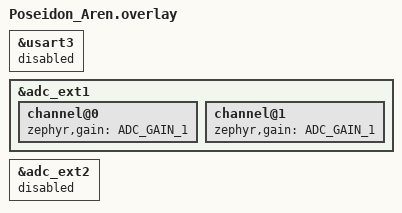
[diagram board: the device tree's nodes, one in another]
/*
 * Device-tree overlay for the "Poseidon_Aren" variant.
 *
 * Cell mix: 2x DiveO2 digital cells (CELL_COUNT=2).
 *
 *   Cell 1 = DiveO2  → USART1
 *   Cell 2 = DiveO2  → USART2
 *   (no Cell 3)      → USART3 unused
 *
 * No analog cells, but the first ADS1115 (adc_ext1 @0x48) is repurposed for
 * the HP tank pressure transducers (CONFIG_O2_TRANSDUCER_CHANNEL=0 /
 * CONFIG_DIL_TRANSDUCER_CHANNEL=1 in the matching .conf):
 *
 *   O2 transducer  → io-channels index 0 → adc_ext1 channel@0 (AIN0-AIN1)
 *   Dil transducer → io-channels index 1 → adc_ext1 channel@1 (AIN2-AIN3)
 *
 * The transducers swing 0.3–1.8 V, so the galvanic-cell PGA range of
 * ADC_GAIN_8 (±0.256 V) from the board DTS would clip: override both
 * channels to ADC_GAIN_1 (±2.048 V full scale).
 *
 * With only two digital cells USART3 is idle, and adc_ext2 (cell 3 + aux)
 * is unused. Disabling those nodes elides each driver's
 * DEVICE_DT_INST_DEFINE, reclaiming ~1,472 B per ADS1115 and ~354 B per
 * USART that would otherwise be allocated at link time.
 *
 * If the cell mix changes (a third cell, or an analog cell), re-enable
 * the matching node here or the build will fail with a missing DT-node
 * reference from the cell driver.
 */

/* Only two cells, both digital — USART3 and the second ADS1115 are unused. */
&usart3 {
    status = "disabled";
};

/* Tank pressure transducers on the analog-cell inputs of adc_ext1. */
&adc_ext1 {
    status = "okay";

    channel@0 {
        zephyr,gain = "ADC_GAIN_1";	/* ±2.048 V — covers the 0.3–1.8 V O2 transducer */
    };

    channel@1 {
        zephyr,gain = "ADC_GAIN_1";	/* ±2.048 V — covers the 0.3–1.8 V dil transducer */
    };
};

&adc_ext2 {
    status = "disabled";
};
